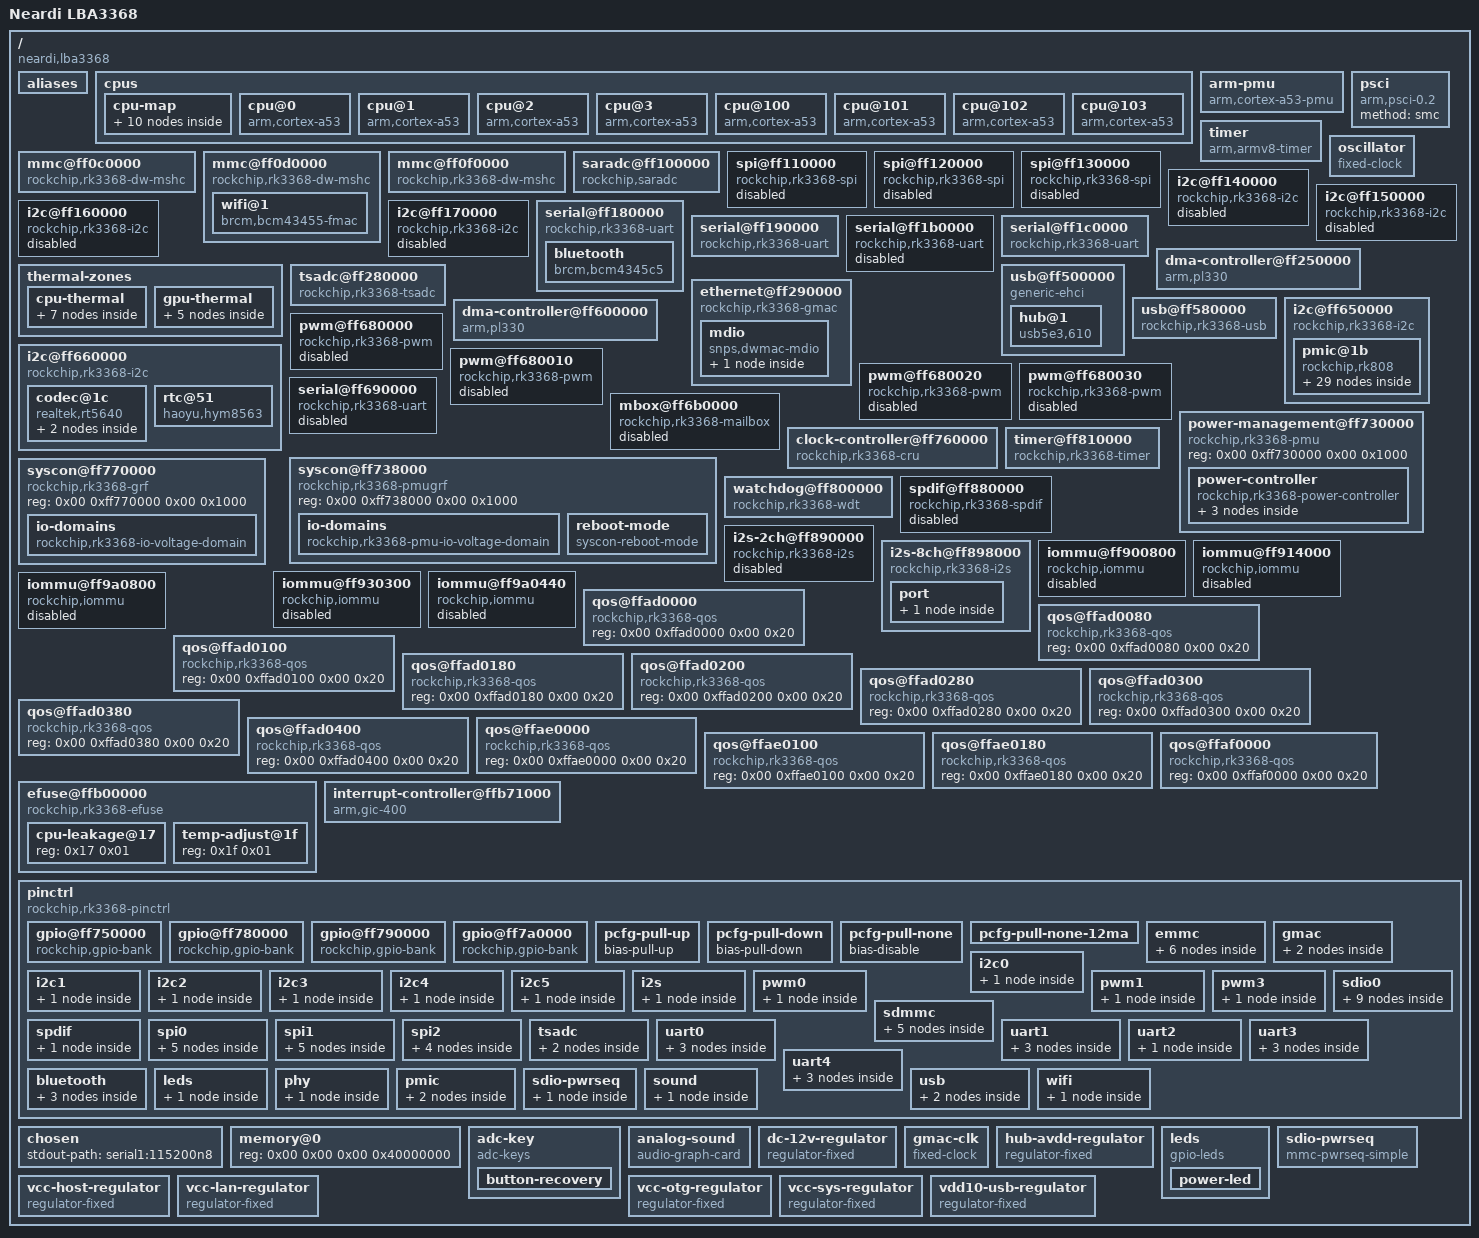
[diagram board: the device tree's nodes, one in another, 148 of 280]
/dts-v1/;

/ {
	compatible = "neardi,lba3368\0rockchip,rk3368";
	interrupt-parent = <0x01>;
	#address-cells = <0x02>;
	#size-cells = <0x02>;
	model = "Neardi LBA3368";

	aliases {
		gpio0 = "/pinctrl/gpio@ff750000";
		gpio1 = "/pinctrl/gpio@ff780000";
		gpio2 = "/pinctrl/gpio@ff790000";
		gpio3 = "/pinctrl/gpio@ff7a0000";
		i2c0 = "/i2c@ff650000";
		i2c1 = "/i2c@ff660000";
		i2c2 = "/i2c@ff140000";
		i2c3 = "/i2c@ff150000";
		i2c4 = "/i2c@ff160000";
		i2c5 = "/i2c@ff170000";
		serial0 = "/serial@ff180000";
		serial1 = "/serial@ff190000";
		serial2 = "/serial@ff690000";
		serial3 = "/serial@ff1b0000";
		serial4 = "/serial@ff1c0000";
		spi0 = "/spi@ff110000";
		spi1 = "/spi@ff120000";
		spi2 = "/spi@ff130000";
		ethernet0 = "/ethernet@ff290000";
		mmc0 = "/mmc@ff0f0000";
		mmc1 = "/mmc@ff0c0000";
		mmc2 = "/mmc@ff0d0000";
		rtc0 = "/i2c@ff660000/rtc@51";
		rtc1 = "/i2c@ff650000/pmic@1b";
	};

	cpus {
		#address-cells = <0x02>;
		#size-cells = <0x00>;

		cpu-map {

			cluster0 {

				core0 {
					cpu = <0x02>;
				};

				core1 {
					cpu = <0x03>;
				};

				core2 {
					cpu = <0x04>;
				};

				core3 {
					cpu = <0x05>;
				};
			};

			cluster1 {

				core0 {
					cpu = <0x06>;
				};

				core1 {
					cpu = <0x07>;
				};

				core2 {
					cpu = <0x08>;
				};

				core3 {
					cpu = <0x09>;
				};
			};
		};

		cpu@0 {
			device_type = "cpu";
			compatible = "arm,cortex-a53";
			reg = <0x00 0x00>;
			enable-method = "psci";
			#cooling-cells = <0x02>;
			cpu-supply = <0x0a>;
			phandle = <0x06>;
		};

		cpu@1 {
			device_type = "cpu";
			compatible = "arm,cortex-a53";
			reg = <0x00 0x01>;
			enable-method = "psci";
			#cooling-cells = <0x02>;
			cpu-supply = <0x0a>;
			phandle = <0x07>;
		};

		cpu@2 {
			device_type = "cpu";
			compatible = "arm,cortex-a53";
			reg = <0x00 0x02>;
			enable-method = "psci";
			#cooling-cells = <0x02>;
			cpu-supply = <0x0a>;
			phandle = <0x08>;
		};

		cpu@3 {
			device_type = "cpu";
			compatible = "arm,cortex-a53";
			reg = <0x00 0x03>;
			enable-method = "psci";
			#cooling-cells = <0x02>;
			cpu-supply = <0x0a>;
			phandle = <0x09>;
		};

		cpu@100 {
			device_type = "cpu";
			compatible = "arm,cortex-a53";
			reg = <0x00 0x100>;
			enable-method = "psci";
			#cooling-cells = <0x02>;
			cpu-supply = <0x0a>;
			phandle = <0x02>;
		};

		cpu@101 {
			device_type = "cpu";
			compatible = "arm,cortex-a53";
			reg = <0x00 0x101>;
			enable-method = "psci";
			#cooling-cells = <0x02>;
			cpu-supply = <0x0a>;
			phandle = <0x03>;
		};

		cpu@102 {
			device_type = "cpu";
			compatible = "arm,cortex-a53";
			reg = <0x00 0x102>;
			enable-method = "psci";
			#cooling-cells = <0x02>;
			cpu-supply = <0x0a>;
			phandle = <0x04>;
		};

		cpu@103 {
			device_type = "cpu";
			compatible = "arm,cortex-a53";
			reg = <0x00 0x103>;
			enable-method = "psci";
			#cooling-cells = <0x02>;
			cpu-supply = <0x0a>;
			phandle = <0x05>;
		};
	};

	arm-pmu {
		compatible = "arm,cortex-a53-pmu";
		interrupts = <0x00 0x70 0x04 0x00 0x71 0x04 0x00 0x72 0x04 0x00 0x73 0x04 0x00 0x74 0x04 0x00 0x75 0x04 0x00 0x76 0x04 0x00 0x77 0x04>;
		interrupt-affinity = <0x06 0x07 0x08 0x09 0x02 0x03 0x04 0x05>;
	};

	psci {
		compatible = "arm,psci-0.2";
		method = "smc";
	};

	timer {
		compatible = "arm,armv8-timer";
		interrupts = <0x01 0x0d 0xff04 0x01 0x0e 0xff04 0x01 0x0b 0xff04 0x01 0x0a 0xff04>;
	};

	oscillator {
		compatible = "fixed-clock";
		clock-frequency = <0x16e3600>;
		clock-output-names = "xin24m";
		#clock-cells = <0x00>;
		phandle = <0x5e>;
	};

	mmc@ff0c0000 {
		compatible = "rockchip,rk3368-dw-mshc\0rockchip,rk3288-dw-mshc";
		reg = <0x00 0xff0c0000 0x00 0x4000>;
		max-frequency = <0x8f0d180>;
		clocks = <0x0b 0x1c8 0x0b 0x44 0x0b 0x72 0x0b 0x76>;
		clock-names = "biu\0ciu\0ciu-drive\0ciu-sample";
		fifo-depth = <0x100>;
		interrupts = <0x00 0x20 0x04>;
		resets = <0x0b 0x80>;
		reset-names = "reset";
		status = "okay";
		bus-width = <0x04>;
		vmmc-supply = <0x0c>;
		vqmmc-supply = <0x0d>;
		pinctrl-names = "default";
		pinctrl-0 = <0x0e 0x0f 0x10 0x11>;
		cap-sd-highspeed;
		disable-wp;
		no-mmc;
		no-sdio;
		sd-uhs-sdr12;
		sd-uhs-sdr25;
		sd-uhs-sdr50;
		sd-uhs-sdr104;
	};

	mmc@ff0d0000 {
		compatible = "rockchip,rk3368-dw-mshc\0rockchip,rk3288-dw-mshc";
		reg = <0x00 0xff0d0000 0x00 0x4000>;
		max-frequency = <0x8f0d180>;
		clocks = <0x0b 0x1c9 0x0b 0x45 0x0b 0x73 0x0b 0x77>;
		clock-names = "biu\0ciu\0ciu-drive\0ciu-sample";
		fifo-depth = <0x100>;
		interrupts = <0x00 0x21 0x04>;
		resets = <0x0b 0x81>;
		reset-names = "reset";
		status = "okay";
		bus-width = <0x04>;
		mmc-pwrseq = <0x12>;
		vmmc-supply = <0x13>;
		vqmmc-supply = <0x14>;
		assigned-clocks = <0x0b 0x45>;
		assigned-clock-parents = <0x0b 0x04>;
		pinctrl-names = "default";
		pinctrl-0 = <0x15 0x16 0x17>;
		cap-sd-highspeed;
		cap-sdio-irq;
		no-sd;
		no-mmc;
		non-removable;
		sd-uhs-sdr104;
		#address-cells = <0x01>;
		#size-cells = <0x00>;

		wifi@1 {
			compatible = "brcm,bcm43455-fmac\0brcm,bcm4329-fmac";
			reg = <0x01>;
			interrupts-extended = <0x18 0x06 0x04>;
			interrupt-names = "host-wake";
			pinctrl-names = "default";
			pinctrl-0 = <0x19>;
		};
	};

	mmc@ff0f0000 {
		compatible = "rockchip,rk3368-dw-mshc\0rockchip,rk3288-dw-mshc";
		reg = <0x00 0xff0f0000 0x00 0x4000>;
		max-frequency = <0x8f0d180>;
		clocks = <0x0b 0x1cb 0x0b 0x47 0x0b 0x75 0x0b 0x79>;
		clock-names = "biu\0ciu\0ciu-drive\0ciu-sample";
		fifo-depth = <0x100>;
		interrupts = <0x00 0x23 0x04>;
		resets = <0x0b 0x83>;
		reset-names = "reset";
		status = "okay";
		bus-width = <0x08>;
		vmmc-supply = <0x13>;
		vqmmc-supply = <0x1a>;
		pinctrl-names = "default";
		pinctrl-0 = <0x1b 0x1c 0x1d>;
		cap-mmc-highspeed;
		non-removable;
		no-sd;
		no-sdio;
		mmc-hs200-1_8v;
	};

	saradc@ff100000 {
		compatible = "rockchip,saradc";
		reg = <0x00 0xff100000 0x00 0x100>;
		interrupts = <0x00 0x24 0x04>;
		#io-channel-cells = <0x01>;
		clocks = <0x0b 0x49 0x0b 0x15b>;
		clock-names = "saradc\0apb_pclk";
		resets = <0x0b 0x57>;
		reset-names = "saradc-apb";
		status = "okay";
		vref-supply = <0x1a>;
		phandle = <0x69>;
	};

	spi@ff110000 {
		compatible = "rockchip,rk3368-spi\0rockchip,rk3066-spi";
		reg = <0x00 0xff110000 0x00 0x1000>;
		clocks = <0x0b 0x41 0x0b 0x152>;
		clock-names = "spiclk\0apb_pclk";
		interrupts = <0x00 0x2c 0x04>;
		pinctrl-names = "default";
		pinctrl-0 = <0x1e 0x1f 0x20 0x21>;
		#address-cells = <0x01>;
		#size-cells = <0x00>;
		status = "disabled";
	};

	spi@ff120000 {
		compatible = "rockchip,rk3368-spi\0rockchip,rk3066-spi";
		reg = <0x00 0xff120000 0x00 0x1000>;
		clocks = <0x0b 0x42 0x0b 0x153>;
		clock-names = "spiclk\0apb_pclk";
		interrupts = <0x00 0x2d 0x04>;
		pinctrl-names = "default";
		pinctrl-0 = <0x22 0x23 0x24 0x25>;
		#address-cells = <0x01>;
		#size-cells = <0x00>;
		status = "disabled";
	};

	spi@ff130000 {
		compatible = "rockchip,rk3368-spi\0rockchip,rk3066-spi";
		reg = <0x00 0xff130000 0x00 0x1000>;
		clocks = <0x0b 0x43 0x0b 0x154>;
		clock-names = "spiclk\0apb_pclk";
		interrupts = <0x00 0x29 0x04>;
		pinctrl-names = "default";
		pinctrl-0 = <0x26 0x27 0x28 0x29>;
		#address-cells = <0x01>;
		#size-cells = <0x00>;
		status = "disabled";
	};

	i2c@ff140000 {
		compatible = "rockchip,rk3368-i2c\0rockchip,rk3288-i2c";
		reg = <0x00 0xff140000 0x00 0x1000>;
		interrupts = <0x00 0x3e 0x04>;
		#address-cells = <0x01>;
		#size-cells = <0x00>;
		clock-names = "i2c";
		clocks = <0x0b 0x14e>;
		pinctrl-names = "default";
		pinctrl-0 = <0x2a>;
		status = "disabled";
	};

	i2c@ff150000 {
		compatible = "rockchip,rk3368-i2c\0rockchip,rk3288-i2c";
		reg = <0x00 0xff150000 0x00 0x1000>;
		interrupts = <0x00 0x3f 0x04>;
		#address-cells = <0x01>;
		#size-cells = <0x00>;
		clock-names = "i2c";
		clocks = <0x0b 0x14f>;
		pinctrl-names = "default";
		pinctrl-0 = <0x2b>;
		status = "disabled";
	};

	i2c@ff160000 {
		compatible = "rockchip,rk3368-i2c\0rockchip,rk3288-i2c";
		reg = <0x00 0xff160000 0x00 0x1000>;
		interrupts = <0x00 0x40 0x04>;
		#address-cells = <0x01>;
		#size-cells = <0x00>;
		clock-names = "i2c";
		clocks = <0x0b 0x150>;
		pinctrl-names = "default";
		pinctrl-0 = <0x2c>;
		status = "disabled";
	};

	i2c@ff170000 {
		compatible = "rockchip,rk3368-i2c\0rockchip,rk3288-i2c";
		reg = <0x00 0xff170000 0x00 0x1000>;
		interrupts = <0x00 0x41 0x04>;
		#address-cells = <0x01>;
		#size-cells = <0x00>;
		clock-names = "i2c";
		clocks = <0x0b 0x151>;
		pinctrl-names = "default";
		pinctrl-0 = <0x2d>;
		status = "disabled";
	};

	serial@ff180000 {
		compatible = "rockchip,rk3368-uart\0snps,dw-apb-uart";
		reg = <0x00 0xff180000 0x00 0x100>;
		clock-frequency = <0x16e3600>;
		clocks = <0x0b 0x4d 0x0b 0x155>;
		clock-names = "baudclk\0apb_pclk";
		interrupts = <0x00 0x37 0x04>;
		reg-shift = <0x02>;
		reg-io-width = <0x04>;
		status = "okay";
		pinctrl-names = "default";
		pinctrl-0 = <0x2e 0x2f 0x30>;
		uart-has-rtscts;

		bluetooth {
			compatible = "brcm,bcm4345c5";
			interrupts-extended = <0x18 0x07 0x00>;
			interrupt-names = "host-wakeup";
			clocks = <0x31 0x01>;
			clock-names = "lpo";
			device-wakeup-gpios = <0x18 0x03 0x00>;
			shutdown-gpios = <0x18 0x02 0x00>;
			max-speed = <0xe4e1c0>;
			vbat-supply = <0x13>;
			vddio-supply = <0x14>;
			pinctrl-names = "default";
			pinctrl-0 = <0x32 0x33 0x34>;
		};
	};

	serial@ff190000 {
		compatible = "rockchip,rk3368-uart\0snps,dw-apb-uart";
		reg = <0x00 0xff190000 0x00 0x100>;
		clock-frequency = <0x16e3600>;
		clocks = <0x0b 0x4e 0x0b 0x156>;
		clock-names = "baudclk\0apb_pclk";
		interrupts = <0x00 0x38 0x04>;
		reg-shift = <0x02>;
		reg-io-width = <0x04>;
		status = "okay";
		pinctrl-names = "default";
		pinctrl-0 = <0x35>;
	};

	serial@ff1b0000 {
		compatible = "rockchip,rk3368-uart\0snps,dw-apb-uart";
		reg = <0x00 0xff1b0000 0x00 0x100>;
		clock-frequency = <0x16e3600>;
		clocks = <0x0b 0x50 0x0b 0x158>;
		clock-names = "baudclk\0apb_pclk";
		interrupts = <0x00 0x3a 0x04>;
		reg-shift = <0x02>;
		reg-io-width = <0x04>;
		status = "disabled";
	};

	serial@ff1c0000 {
		compatible = "rockchip,rk3368-uart\0snps,dw-apb-uart";
		reg = <0x00 0xff1c0000 0x00 0x100>;
		clock-frequency = <0x16e3600>;
		clocks = <0x0b 0x51 0x0b 0x159>;
		clock-names = "baudclk\0apb_pclk";
		interrupts = <0x00 0x3b 0x04>;
		reg-shift = <0x02>;
		reg-io-width = <0x04>;
		status = "okay";
		pinctrl-names = "default";
		pinctrl-0 = <0x36>;
	};

	dma-controller@ff250000 {
		compatible = "arm,pl330\0arm,primecell";
		reg = <0x00 0xff250000 0x00 0x4000>;
		interrupts = <0x00 0x02 0x04 0x00 0x03 0x04>;
		#dma-cells = <0x01>;
		arm,pl330-broken-no-flushp;
		arm,pl330-periph-burst;
		clocks = <0x0b 0xc3>;
		clock-names = "apb_pclk";
	};

	thermal-zones {

		cpu-thermal {
			polling-delay-passive = <0x64>;
			polling-delay = <0x1388>;
			thermal-sensors = <0x37 0x00>;

			trips {

				cpu_alert0 {
					temperature = <0x124f8>;
					hysteresis = <0x7d0>;
					type = "passive";
					phandle = <0x38>;
				};

				cpu_alert1 {
					temperature = <0x13880>;
					hysteresis = <0x7d0>;
					type = "passive";
					phandle = <0x39>;
				};

				cpu_crit {
					temperature = <0x17318>;
					hysteresis = <0x7d0>;
					type = "critical";
				};
			};

			cooling-maps {

				map0 {
					trip = <0x38>;
					cooling-device = <0x02 0xffffffff 0xffffffff 0x03 0xffffffff 0xffffffff 0x04 0xffffffff 0xffffffff 0x05 0xffffffff 0xffffffff>;
				};

				map1 {
					trip = <0x39>;
					cooling-device = <0x06 0xffffffff 0xffffffff 0x07 0xffffffff 0xffffffff 0x08 0xffffffff 0xffffffff 0x09 0xffffffff 0xffffffff>;
				};
			};
		};

		gpu-thermal {
			polling-delay-passive = <0x64>;
			polling-delay = <0x1388>;
			thermal-sensors = <0x37 0x01>;

			trips {

				gpu_alert0 {
					temperature = <0x13880>;
					hysteresis = <0x7d0>;
					type = "passive";
					phandle = <0x3a>;
				};

				gpu_crit {
					temperature = <0x1c138>;
					hysteresis = <0x7d0>;
					type = "critical";
				};
			};

			cooling-maps {

				map0 {
					trip = <0x3a>;
					cooling-device = <0x02 0xffffffff 0xffffffff 0x03 0xffffffff 0xffffffff 0x04 0xffffffff 0xffffffff 0x05 0xffffffff 0xffffffff>;
				};
			};
		};
	};

	tsadc@ff280000 {
		compatible = "rockchip,rk3368-tsadc";
		reg = <0x00 0xff280000 0x00 0x100>;
		interrupts = <0x00 0x25 0x04>;
		clocks = <0x0b 0x48 0x0b 0x15a>;
		clock-names = "tsadc\0apb_pclk";
		resets = <0x0b 0x9f>;
		reset-names = "tsadc-apb";
		pinctrl-names = "init\0default\0sleep";
		pinctrl-0 = <0x3b>;
		pinctrl-1 = <0x3c>;
		pinctrl-2 = <0x3b>;
		#thermal-sensor-cells = <0x01>;
		rockchip,hw-tshut-temp = <0x17318>;
		status = "okay";
		rockchip,hw-tshut-mode = <0x00>;
		rockchip,hw-tshut-polarity = <0x01>;
		phandle = <0x37>;
	};

	ethernet@ff290000 {
		compatible = "rockchip,rk3368-gmac";
		reg = <0x00 0xff290000 0x00 0x10000>;
		interrupts = <0x00 0x1b 0x04>;
		interrupt-names = "macirq";
		rockchip,grf = <0x3d>;
		clocks = <0x0b 0x7f 0x0b 0x66 0x0b 0x67 0x0b 0x63 0x0b 0x80 0x0b 0xc5 0x0b 0x15d>;
		clock-names = "stmmaceth\0mac_clk_rx\0mac_clk_tx\0clk_mac_ref\0clk_mac_refout\0aclk_mac\0pclk_mac";
		status = "okay";
		clock_in_out = "input";
		phy-handle = <0x3e>;
		phy-mode = "rmii";
		phy-supply = <0x3f>;
		assigned-clocks = <0x0b 0x7f>;
		assigned-clock-parents = <0x40>;
		pinctrl-names = "default";
		pinctrl-0 = <0x41>;

		mdio {
			compatible = "snps,dwmac-mdio";
			#address-cells = <0x01>;
			#size-cells = <0x00>;

			ethernet-phy@1 {
				compatible = "ethernet-phy-ieee802.3-c22";
				reg = <0x01>;
				max-speed = <0x64>;
				reset-assert-us = <0x2710>;
				reset-deassert-us = <0xf4240>;
				reset-gpios = <0x18 0x0c 0x01>;
				pinctrl-names = "default";
				pinctrl-0 = <0x42>;
				phandle = <0x3e>;
			};
		};
	};

	usb@ff500000 {
		compatible = "generic-ehci";
		reg = <0x00 0xff500000 0x00 0x100>;
		interrupts = <0x00 0x18 0x04>;
		clocks = <0x0b 0x1c2>;
		status = "okay";
		#address-cells = <0x01>;
		#size-cells = <0x00>;

		hub@1 {
			compatible = "usb5e3,610";
			reg = <0x01>;
			vdd-supply = <0x43>;
		};
	};

	usb@ff580000 {
		compatible = "rockchip,rk3368-usb\0rockchip,rk3066-usb\0snps,dwc2";
		reg = <0x00 0xff580000 0x00 0x40000>;
		interrupts = <0x00 0x17 0x04>;
		clocks = <0x0b 0x1c1>;
		clock-names = "otg";
		dr_mode = "otg";
		g-np-tx-fifo-size = <0x10>;
		g-rx-fifo-size = <0x113>;
		g-tx-fifo-size = <0x100 0x80 0x80 0x40 0x40 0x20>;
		status = "okay";
		vbus-supply = <0x44>;
		vusb_a-supply = <0x13>;
		vusb_d-supply = <0x45>;
	};

	dma-controller@ff600000 {
		compatible = "arm,pl330\0arm,primecell";
		reg = <0x00 0xff600000 0x00 0x4000>;
		interrupts = <0x00 0x00 0x04 0x00 0x01 0x04>;
		#dma-cells = <0x01>;
		arm,pl330-broken-no-flushp;
		arm,pl330-periph-burst;
		clocks = <0x0b 0xc2>;
		clock-names = "apb_pclk";
		phandle = <0x60>;
	};

	i2c@ff650000 {
		compatible = "rockchip,rk3368-i2c\0rockchip,rk3288-i2c";
		reg = <0x00 0xff650000 0x00 0x1000>;
		clocks = <0x0b 0x14c>;
		clock-names = "i2c";
		interrupts = <0x00 0x3c 0x04>;
		pinctrl-names = "default";
		pinctrl-0 = <0x46>;
		#address-cells = <0x01>;
		#size-cells = <0x00>;
		status = "okay";

		pmic@1b {
			compatible = "rockchip,rk808";
			reg = <0x1b>;
			interrupts-extended = <0x47 0x05 0x08>;
			clock-output-names = "rk808-clkout1\0xin32k_wifi_bt";
			vcc1-supply = <0x48>;
			vcc2-supply = <0x48>;
			vcc3-supply = <0x48>;
			vcc4-supply = <0x48>;
			vcc6-supply = <0x48>;
			vcc7-supply = <0x48>;
			vcc8-supply = <0x13>;
			vcc9-supply = <0x48>;
			vcc10-supply = <0x48>;
			vcc11-supply = <0x48>;
			vcc12-supply = <0x13>;
			pinctrl-names = "default";
			pinctrl-0 = <0x49 0x4a>;
			system-power-controller;
			wakeup-source;
			#clock-cells = <0x01>;
			phandle = <0x31>;

			regulators {

				DCDC_REG1 {
					regulator-name = "vdd_cpu";
					regulator-min-microvolt = <0xaae60>;
					regulator-max-microvolt = <0x149970>;
					regulator-always-on;
					regulator-boot-on;
					phandle = <0x0a>;

					regulator-state-mem {
						regulator-off-in-suspend;
					};
				};

				DCDC_REG2 {
					regulator-name = "vdd_log";
					regulator-min-microvolt = <0x10c8e0>;
					regulator-max-microvolt = <0x16e360>;
					regulator-ramp-delay = <0x1771>;
					regulator-always-on;
					regulator-boot-on;

					regulator-state-mem {
						regulator-suspend-microvolt = <0xf4240>;
						regulator-on-in-suspend;
					};
				};

				DCDC_REG3 {
					regulator-name = "vcc_ddr";
					regulator-always-on;
					regulator-boot-on;

					regulator-state-mem {
						regulator-on-in-suspend;
					};
				};

				DCDC_REG4 {
					regulator-name = "vcc_io";
					regulator-min-microvolt = <0x325aa0>;
					regulator-max-microvolt = <0x325aa0>;
					regulator-always-on;
					regulator-boot-on;
					phandle = <0x13>;

					regulator-state-mem {
						regulator-suspend-microvolt = <0x325aa0>;
						regulator-on-in-suspend;
					};
				};

				LDO_REG1 {
					regulator-name = "vcca1v8_codec";
					regulator-min-microvolt = <0x1b7740>;
					regulator-max-microvolt = <0x1b7740>;
					regulator-always-on;
					phandle = <0x5f>;

					regulator-state-mem {
						regulator-off-in-suspend;
					};
				};

				LDO_REG2 {
					regulator-name = "vcca3v0_codec";
					regulator-min-microvolt = <0x2dc6c0>;
					regulator-max-microvolt = <0x2dc6c0>;
					regulator-always-on;

					regulator-state-mem {
						regulator-off-in-suspend;
					};
				};

				LDO_REG3 {
					regulator-name = "vdd_10";
					regulator-min-microvolt = <0xf4240>;
					regulator-max-microvolt = <0xf4240>;
					regulator-always-on;
					regulator-boot-on;
					phandle = <0x71>;

					regulator-state-mem {
						regulator-suspend-microvolt = <0xf4240>;
						regulator-on-in-suspend;
					};
				};

				LDO_REG4 {
					regulator-name = "vdd1v8_wl";
					regulator-min-microvolt = <0x1b7740>;
					regulator-max-microvolt = <0x1b7740>;
					phandle = <0x14>;

					regulator-state-mem {
						regulator-off-in-suspend;
					};
				};

				LDO_REG5 {
					regulator-name = "vccio_sd";
					regulator-min-microvolt = <0x1b7740>;
					regulator-max-microvolt = <0x325aa0>;
					phandle = <0x0d>;

					regulator-state-mem {
						regulator-off-in-suspend;
					};
				};

				LDO_REG6 {
					regulator-name = "vdd10_lcd";
					regulator-min-microvolt = <0xf4240>;
					regulator-max-microvolt = <0xf4240>;

					regulator-state-mem {
						regulator-off-in-suspend;
					};
				};

				LDO_REG7 {
					regulator-name = "vcc_18";
					regulator-min-microvolt = <0x1b7740>;
					regulator-max-microvolt = <0x1b7740>;
					phandle = <0x1a>;

					regulator-state-mem {
						regulator-suspend-microvolt = <0x1b7740>;
						regulator-on-in-suspend;
					};
				};

				LDO_REG8 {
					regulator-name = "vcc18_lcd";
					regulator-min-microvolt = <0x1b7740>;
					regulator-max-microvolt = <0x1b7740>;

					regulator-state-mem {
						regulator-off-in-suspend;
					};
				};

				SWITCH_REG1 {
					regulator-name = "vcc_tp";

					regulator-state-mem {
						regulator-on-in-suspend;
					};
				};

				SWITCH_REG2 {
					regulator-name = "vcc_sd";
					phandle = <0x0c>;

					regulator-state-mem {
						regulator-off-in-suspend;
					};
				};
			};
		};
	};

	i2c@ff660000 {
		compatible = "rockchip,rk3368-i2c\0rockchip,rk3288-i2c";
		reg = <0x00 0xff660000 0x00 0x1000>;
		interrupts = <0x00 0x3d 0x04>;
		#address-cells = <0x01>;
		#size-cells = <0x00>;
		clock-names = "i2c";
		clocks = <0x0b 0x14d>;
		pinctrl-names = "default";
		pinctrl-0 = <0x4b>;
		status = "okay";

		codec@1c {
			compatible = "realtek,rt5640";
			reg = <0x1c>;
			clocks = <0x0b 0x71>;
			clock-names = "mclk";
			realtek,dmic1-data-pin = <0x01>;
			realtek,dmic2-data-pin = <0x01>;
			realtek,in1-differential;
			#sound-dai-cells = <0x00>;

			port {

				endpoint {
					remote-endpoint = <0x4c>;
					phandle = <0x63>;
				};
			};
		};

		rtc@51 {
			compatible = "haoyu,hym8563";
			reg = <0x51>;
			clock-output-names = "xin32k";
			#clock-cells = <0x00>;
		};
	};

	pwm@ff680000 {
		compatible = "rockchip,rk3368-pwm\0rockchip,rk3288-pwm";
		reg = <0x00 0xff680000 0x00 0x10>;
		#pwm-cells = <0x03>;
		pinctrl-names = "default";
		pinctrl-0 = <0x4d>;
		clocks = <0x0b 0x15f>;
		status = "disabled";
	};

	pwm@ff680010 {
		compatible = "rockchip,rk3368-pwm\0rockchip,rk3288-pwm";
		reg = <0x00 0xff680010 0x00 0x10>;
		#pwm-cells = <0x03>;
		pinctrl-names = "default";
		pinctrl-0 = <0x4e>;
		clocks = <0x0b 0x15f>;
		status = "disabled";
	};

	pwm@ff680020 {
		compatible = "rockchip,rk3368-pwm\0rockchip,rk3288-pwm";
		reg = <0x00 0xff680020 0x00 0x10>;
		#pwm-cells = <0x03>;
		clocks = <0x0b 0x15f>;
		status = "disabled";
	};

	pwm@ff680030 {
		compatible = "rockchip,rk3368-pwm\0rockchip,rk3288-pwm";
		reg = <0x00 0xff680030 0x00 0x10>;
		#pwm-cells = <0x03>;
		pinctrl-names = "default";
		pinctrl-0 = <0x4f>;
		clocks = <0x0b 0x15f>;
		status = "disabled";
	};

	serial@ff690000 {
		compatible = "rockchip,rk3368-uart\0snps,dw-apb-uart";
		reg = <0x00 0xff690000 0x00 0x100>;
		clocks = <0x0b 0x4f 0x0b 0x157>;
		clock-names = "baudclk\0apb_pclk";
		interrupts = <0x00 0x39 0x04>;
		pinctrl-names = "default";
		pinctrl-0 = <0x50>;
		reg-shift = <0x02>;
		reg-io-width = <0x04>;
		status = "disabled";
	};

	mbox@ff6b0000 {
		compatible = "rockchip,rk3368-mailbox";
		reg = <0x00 0xff6b0000 0x00 0x1000>;
		interrupts = <0x00 0x92 0x04 0x00 0x93 0x04 0x00 0x94 0x04 0x00 0x95 0x04>;
		clocks = <0x0b 0x145>;
		clock-names = "pclk_mailbox";
		#mbox-cells = <0x01>;
		status = "disabled";
	};

	power-management@ff730000 {
		compatible = "rockchip,rk3368-pmu\0syscon\0simple-mfd";
		reg = <0x00 0xff730000 0x00 0x1000>;

		power-controller {
			compatible = "rockchip,rk3368-power-controller";
			#power-domain-cells = <0x01>;
			#address-cells = <0x01>;
			#size-cells = <0x00>;
			phandle = <0x64>;

			power-domain@12 {
				reg = <0x0c>;
				clocks = <0x0b 0xca 0x0b 0xcd 0x0b 0xcc 0x0b 0xc8 0x0b 0xc6 0x0b 0xc7 0x0b 0xbe 0x0b 0x1d4 0x0b 0x1d5 0x0b 0x1d6 0x0b 0x1d9 0x0b 0x1d1 0x0b 0x1db 0x0b 0x163 0x0b 0x168 0x0b 0x167 0x0b 0x16e 0x0b 0x16f 0x0b 0x172 0x0b 0x173 0x0b 0x166 0x0b 0x164 0x0b 0x64 0x0b 0x68 0x0b 0x69 0x0b 0x6c 0x0b 0x6b 0x0b 0x6a 0x0b 0x6e 0x0b 0x6d>;
				pm_qos = <0x51 0x52 0x53 0x54 0x55 0x56 0x57 0x58 0x59>;
				#power-domain-cells = <0x00>;
			};

			power-domain@14 {
				reg = <0x0e>;
				clocks = <0x0b 0xd0 0x0b 0x1dc 0x0b 0x6f 0x0b 0x70>;
				pm_qos = <0x5a 0x5b 0x5c>;
				#power-domain-cells = <0x00>;
			};

			power-domain@16 {
				reg = <0x10>;
				clocks = <0x0b 0xc1 0x0b 0xc0 0x0b 0x40>;
				pm_qos = <0x5d>;
				#power-domain-cells = <0x00>;
			};
		};
	};

	syscon@ff738000 {
		compatible = "rockchip,rk3368-pmugrf\0syscon\0simple-mfd";
		reg = <0x00 0xff738000 0x00 0x1000>;
		phandle = <0x65>;

		io-domains {
			compatible = "rockchip,rk3368-pmu-io-voltage-domain";
			status = "okay";
			pmu-supply = <0x13>;
			vop-supply = <0x13>;
		};

		reboot-mode {
			compatible = "syscon-reboot-mode";
			offset = <0x200>;
			mode-normal = <0x5242c300>;
			mode-recovery = <0x5242c303>;
			mode-bootloader = <0x5242c309>;
			mode-loader = <0x5242c301>;
		};
	};

	clock-controller@ff760000 {
		compatible = "rockchip,rk3368-cru";
		reg = <0x00 0xff760000 0x00 0x1000>;
		clocks = <0x5e>;
		clock-names = "xin24m";
		rockchip,grf = <0x3d>;
		#clock-cells = <0x01>;
		#reset-cells = <0x01>;
		phandle = <0x0b>;
	};

	syscon@ff770000 {
		compatible = "rockchip,rk3368-grf\0syscon\0simple-mfd";
		reg = <0x00 0xff770000 0x00 0x1000>;
		phandle = <0x3d>;

		io-domains {
			compatible = "rockchip,rk3368-io-voltage-domain";
			status = "okay";
			audio-supply = <0x5f>;
			dvp-supply = <0x1a>;
			flash0-supply = <0x1a>;
			gpio1830-supply = <0x13>;
			gpio30-supply = <0x13>;
			sdcard-supply = <0x0d>;
			wifi-supply = <0x14>;
		};
	};

	watchdog@ff800000 {
		compatible = "rockchip,rk3368-wdt\0snps,dw-wdt";
		reg = <0x00 0xff800000 0x00 0x100>;
		clocks = <0x0b 0x170>;
		interrupts = <0x00 0x4f 0x04>;
		status = "okay";
	};

	timer@ff810000 {
		compatible = "rockchip,rk3368-timer\0rockchip,rk3288-timer";
		reg = <0x00 0xff810000 0x00 0x20>;
		interrupts = <0x00 0x42 0x04>;
		clocks = <0x0b 0x161 0x0b 0x55>;
		clock-names = "pclk\0timer";
	};

	spdif@ff880000 {
		compatible = "rockchip,rk3368-spdif";
		reg = <0x00 0xff880000 0x00 0x1000>;
		interrupts = <0x00 0x36 0x04>;
		clocks = <0x0b 0x53 0x0b 0x1d0>;
		clock-names = "mclk\0hclk";
		dmas = <0x60 0x03>;
		dma-names = "tx";
		pinctrl-names = "default";
		pinctrl-0 = <0x61>;
		#sound-dai-cells = <0x00>;
		status = "disabled";
	};

	i2s-2ch@ff890000 {
		compatible = "rockchip,rk3368-i2s\0rockchip,rk3066-i2s";
		reg = <0x00 0xff890000 0x00 0x1000>;
		interrupts = <0x00 0x28 0x04>;
		clock-names = "i2s_clk\0i2s_hclk";
		clocks = <0x0b 0x54 0x0b 0x1ce>;
		dmas = <0x60 0x06 0x60 0x07>;
		dma-names = "tx\0rx";
		#sound-dai-cells = <0x00>;
		status = "disabled";
	};

	i2s-8ch@ff898000 {
		compatible = "rockchip,rk3368-i2s\0rockchip,rk3066-i2s";
		reg = <0x00 0xff898000 0x00 0x1000>;
		interrupts = <0x00 0x35 0x04>;
		clock-names = "i2s_clk\0i2s_hclk";
		clocks = <0x0b 0x52 0x0b 0x1cf>;
		dmas = <0x60 0x00 0x60 0x01>;
		dma-names = "tx\0rx";
		pinctrl-names = "default";
		pinctrl-0 = <0x62>;
		#sound-dai-cells = <0x00>;
		status = "okay";

		port {
			phandle = <0x6a>;

			endpoint {
				dai-format = "i2s";
				mclk-fs = <0x100>;
				remote-endpoint = <0x63>;
				phandle = <0x4c>;
			};
		};
	};

	iommu@ff900800 {
		compatible = "rockchip,iommu";
		reg = <0x00 0xff900800 0x00 0x100>;
		interrupts = <0x00 0x11 0x04>;
		clocks = <0x0b 0xca 0x0b 0x1d4>;
		clock-names = "aclk\0iface";
		power-domains = <0x64 0x0c>;
		#iommu-cells = <0x00>;
		status = "disabled";
	};

	iommu@ff914000 {
		compatible = "rockchip,iommu";
		reg = <0x00 0xff914000 0x00 0x100 0x00 0xff915000 0x00 0x100>;
		interrupts = <0x00 0x0e 0x04>;
		clocks = <0x0b 0xcd 0x0b 0x1d5>;
		clock-names = "aclk\0iface";
		#iommu-cells = <0x00>;
		power-domains = <0x64 0x0c>;
		rockchip,disable-mmu-reset;
		status = "disabled";
	};

	iommu@ff930300 {
		compatible = "rockchip,iommu";
		reg = <0x00 0xff930300 0x00 0x100>;
		interrupts = <0x00 0x0f 0x04>;
		clocks = <0x0b 0xc6 0x0b 0x1d1>;
		clock-names = "aclk\0iface";
		power-domains = <0x64 0x0c>;
		#iommu-cells = <0x00>;
		status = "disabled";
	};

	iommu@ff9a0440 {
		compatible = "rockchip,iommu";
		reg = <0x00 0xff9a0440 0x00 0x40 0x00 0xff9a0480 0x00 0x40>;
		interrupts = <0x00 0x0c 0x04>;
		clocks = <0x0b 0xd0 0x0b 0x1dc>;
		clock-names = "aclk\0iface";
		#iommu-cells = <0x00>;
		status = "disabled";
	};

	iommu@ff9a0800 {
		compatible = "rockchip,iommu";
		reg = <0x00 0xff9a0800 0x00 0x100>;
		interrupts = <0x00 0x09 0x04 0x00 0x0a 0x04>;
		clocks = <0x0b 0xd0 0x0b 0x1dc>;
		clock-names = "aclk\0iface";
		#iommu-cells = <0x00>;
		status = "disabled";
	};

	qos@ffad0000 {
		compatible = "rockchip,rk3368-qos\0syscon";
		reg = <0x00 0xffad0000 0x00 0x20>;
		phandle = <0x51>;
	};

	qos@ffad0080 {
		compatible = "rockchip,rk3368-qos\0syscon";
		reg = <0x00 0xffad0080 0x00 0x20>;
		phandle = <0x52>;
	};

	qos@ffad0100 {
		compatible = "rockchip,rk3368-qos\0syscon";
		reg = <0x00 0xffad0100 0x00 0x20>;
		phandle = <0x53>;
	};

	qos@ffad0180 {
		compatible = "rockchip,rk3368-qos\0syscon";
		reg = <0x00 0xffad0180 0x00 0x20>;
		phandle = <0x54>;
	};

	qos@ffad0200 {
		compatible = "rockchip,rk3368-qos\0syscon";
		reg = <0x00 0xffad0200 0x00 0x20>;
		phandle = <0x55>;
	};

	qos@ffad0280 {
		compatible = "rockchip,rk3368-qos\0syscon";
		reg = <0x00 0xffad0280 0x00 0x20>;
		phandle = <0x56>;
	};

	qos@ffad0300 {
		compatible = "rockchip,rk3368-qos\0syscon";
		reg = <0x00 0xffad0300 0x00 0x20>;
		phandle = <0x57>;
	};

	qos@ffad0380 {
		compatible = "rockchip,rk3368-qos\0syscon";
		reg = <0x00 0xffad0380 0x00 0x20>;
		phandle = <0x58>;
	};

	qos@ffad0400 {
		compatible = "rockchip,rk3368-qos\0syscon";
		reg = <0x00 0xffad0400 0x00 0x20>;
		phandle = <0x59>;
	};

	qos@ffae0000 {
		compatible = "rockchip,rk3368-qos\0syscon";
		reg = <0x00 0xffae0000 0x00 0x20>;
		phandle = <0x5a>;
	};

	qos@ffae0100 {
		compatible = "rockchip,rk3368-qos\0syscon";
		reg = <0x00 0xffae0100 0x00 0x20>;
		phandle = <0x5b>;
	};

	qos@ffae0180 {
		compatible = "rockchip,rk3368-qos\0syscon";
		reg = <0x00 0xffae0180 0x00 0x20>;
		phandle = <0x5c>;
	};

	qos@ffaf0000 {
		compatible = "rockchip,rk3368-qos\0syscon";
		reg = <0x00 0xffaf0000 0x00 0x20>;
		phandle = <0x5d>;
	};

	efuse@ffb00000 {
		compatible = "rockchip,rk3368-efuse";
		reg = <0x00 0xffb00000 0x00 0x20>;
		#address-cells = <0x01>;
		#size-cells = <0x01>;
		clocks = <0x0b 0x171>;
		clock-names = "pclk_efuse";

		cpu-leakage@17 {
			reg = <0x17 0x01>;
		};

		temp-adjust@1f {
			reg = <0x1f 0x01>;
		};
	};

	interrupt-controller@ffb71000 {
		compatible = "arm,gic-400";
		interrupt-controller;
		#interrupt-cells = <0x03>;
		#address-cells = <0x00>;
		reg = <0x00 0xffb71000 0x00 0x1000 0x00 0xffb72000 0x00 0x2000 0x00 0xffb74000 0x00 0x2000 0x00 0xffb76000 0x00 0x2000>;
		interrupts = <0x01 0x09 0xff04>;
		phandle = <0x01>;
	};

	pinctrl {
		compatible = "rockchip,rk3368-pinctrl";
		rockchip,grf = <0x3d>;
		rockchip,pmu = <0x65>;
		#address-cells = <0x02>;
		#size-cells = <0x02>;
		ranges;

		gpio@ff750000 {
			compatible = "rockchip,gpio-bank";
			reg = <0x00 0xff750000 0x00 0x100>;
			clocks = <0x0b 0x140>;
			interrupts = <0x00 0x51 0x04>;
			gpio-controller;
			#gpio-cells = <0x02>;
			interrupt-controller;
			#interrupt-cells = <0x02>;
			phandle = <0x47>;
		};

		gpio@ff780000 {
			compatible = "rockchip,gpio-bank";
			reg = <0x00 0xff780000 0x00 0x100>;
			clocks = <0x0b 0x141>;
			interrupts = <0x00 0x52 0x04>;
			gpio-controller;
			#gpio-cells = <0x02>;
			interrupt-controller;
			#interrupt-cells = <0x02>;
		};

		gpio@ff790000 {
			compatible = "rockchip,gpio-bank";
			reg = <0x00 0xff790000 0x00 0x100>;
			clocks = <0x0b 0x142>;
			interrupts = <0x00 0x53 0x04>;
			gpio-controller;
			#gpio-cells = <0x02>;
			interrupt-controller;
			#interrupt-cells = <0x02>;
		};

		gpio@ff7a0000 {
			compatible = "rockchip,gpio-bank";
			reg = <0x00 0xff7a0000 0x00 0x100>;
			clocks = <0x0b 0x143>;
			interrupts = <0x00 0x54 0x04>;
			gpio-controller;
			#gpio-cells = <0x02>;
			interrupt-controller;
			#interrupt-cells = <0x02>;
			phandle = <0x18>;
		};

		pcfg-pull-up {
			bias-pull-up;
			phandle = <0x67>;
		};

		pcfg-pull-down {
			bias-pull-down;
		};

		pcfg-pull-none {
			bias-disable;
			phandle = <0x66>;
		};

		pcfg-pull-none-12ma {
			bias-disable;
			drive-strength = <0x0c>;
			phandle = <0x68>;
		};

		emmc {

			emmc-clk {
				rockchip,pins = <0x02 0x04 0x02 0x66>;
				phandle = <0x1b>;
			};

			emmc-cmd {
				rockchip,pins = <0x01 0x1a 0x02 0x67>;
				phandle = <0x1c>;
			};

			emmc-pwr {
				rockchip,pins = <0x01 0x1b 0x02 0x67>;
			};

			emmc-bus1 {
				rockchip,pins = <0x01 0x12 0x02 0x67>;
			};

			emmc-bus4 {
				rockchip,pins = <0x01 0x12 0x02 0x67 0x01 0x13 0x02 0x67 0x01 0x14 0x02 0x67 0x01 0x15 0x02 0x67>;
			};

			emmc-bus8 {
				rockchip,pins = <0x01 0x12 0x02 0x67 0x01 0x13 0x02 0x67 0x01 0x14 0x02 0x67 0x01 0x15 0x02 0x67 0x01 0x16 0x02 0x67 0x01 0x17 0x02 0x67 0x01 0x18 0x02 0x67 0x01 0x19 0x02 0x67>;
				phandle = <0x1d>;
			};
		};

		gmac {

			rgmii-pins {
				rockchip,pins = <0x03 0x16 0x01 0x66 0x03 0x18 0x01 0x66 0x03 0x13 0x01 0x66 0x03 0x08 0x01 0x68 0x03 0x09 0x01 0x68 0x03 0x0a 0x01 0x68 0x03 0x0e 0x01 0x68 0x03 0x1c 0x01 0x68 0x03 0x0d 0x01 0x68 0x03 0x0f 0x01 0x66 0x03 0x10 0x01 0x66 0x03 0x11 0x01 0x66 0x03 0x12 0x01 0x66 0x03 0x19 0x01 0x66 0x03 0x14 0x01 0x66>;
			};

			rmii-pins {
				rockchip,pins = <0x03 0x16 0x01 0x66 0x03 0x18 0x01 0x66 0x03 0x13 0x01 0x66 0x03 0x08 0x01 0x68 0x03 0x09 0x01 0x68 0x03 0x0d 0x01 0x68 0x03 0x0f 0x01 0x66 0x03 0x10 0x01 0x66 0x03 0x14 0x01 0x66 0x03 0x15 0x01 0x66>;
				phandle = <0x41>;
			};
		};

		i2c0 {

			i2c0-xfer {
				rockchip,pins = <0x00 0x06 0x01 0x66 0x00 0x07 0x01 0x66>;
				phandle = <0x46>;
			};
		};

		i2c1 {

			i2c1-xfer {
				rockchip,pins = <0x02 0x15 0x01 0x66 0x02 0x16 0x01 0x66>;
				phandle = <0x4b>;
			};
		};

		i2c2 {

			i2c2-xfer {
				rockchip,pins = <0x00 0x09 0x02 0x66 0x03 0x1f 0x02 0x66>;
				phandle = <0x2a>;
			};
		};

		i2c3 {

			i2c3-xfer {
				rockchip,pins = <0x01 0x10 0x01 0x66 0x01 0x11 0x01 0x66>;
				phandle = <0x2b>;
			};
		};

		i2c4 {

			i2c4-xfer {
				rockchip,pins = <0x03 0x18 0x02 0x66 0x03 0x19 0x02 0x66>;
				phandle = <0x2c>;
			};
		};

		i2c5 {

			i2c5-xfer {
				rockchip,pins = <0x03 0x1a 0x02 0x66 0x03 0x1b 0x02 0x66>;
				phandle = <0x2d>;
			};
		};

		i2s {

			i2s-8ch-bus {
				rockchip,pins = <0x02 0x0c 0x01 0x66 0x02 0x0d 0x01 0x66 0x02 0x0e 0x01 0x66 0x02 0x0f 0x01 0x66 0x02 0x10 0x01 0x66 0x02 0x11 0x01 0x66 0x02 0x12 0x01 0x66 0x02 0x13 0x01 0x66 0x02 0x14 0x01 0x66>;
				phandle = <0x62>;
			};
		};

		pwm0 {

			pwm0-pin {
				rockchip,pins = <0x03 0x08 0x02 0x66>;
				phandle = <0x4d>;
			};
		};

		pwm1 {

			pwm1-pin {
				rockchip,pins = <0x00 0x08 0x02 0x66>;
				phandle = <0x4e>;
			};
		};

		pwm3 {

			pwm3-pin {
				rockchip,pins = <0x03 0x1d 0x03 0x66>;
				phandle = <0x4f>;
			};
		};

		sdio0 {

			sdio0-bus1 {
				rockchip,pins = <0x02 0x1c 0x01 0x67>;
			};

			sdio0-bus4 {
				rockchip,pins = <0x02 0x1c 0x01 0x67 0x02 0x1d 0x01 0x67 0x02 0x1e 0x01 0x67 0x02 0x1f 0x01 0x67>;
				phandle = <0x15>;
			};

			sdio0-cmd {
				rockchip,pins = <0x03 0x00 0x01 0x67>;
				phandle = <0x16>;
			};

			sdio0-clk {
				rockchip,pins = <0x03 0x01 0x01 0x66>;
				phandle = <0x17>;
			};

			sdio0-cd {
				rockchip,pins = <0x03 0x02 0x01 0x67>;
			};

			sdio0-wp {
				rockchip,pins = <0x03 0x03 0x01 0x67>;
			};

			sdio0-pwr {
				rockchip,pins = <0x03 0x04 0x01 0x67>;
			};

			sdio0-bkpwr {
				rockchip,pins = <0x03 0x05 0x01 0x67>;
			};

			sdio0-int {
				rockchip,pins = <0x03 0x06 0x01 0x67>;
			};
		};

		sdmmc {

			sdmmc-clk {
				rockchip,pins = <0x02 0x09 0x01 0x66>;
				phandle = <0x0e>;
			};

			sdmmc-cmd {
				rockchip,pins = <0x02 0x0a 0x01 0x67>;
				phandle = <0x0f>;
			};

			sdmmc-cd {
				rockchip,pins = <0x02 0x0b 0x01 0x67>;
				phandle = <0x11>;
			};

			sdmmc-bus1 {
				rockchip,pins = <0x02 0x05 0x01 0x67>;
			};

			sdmmc-bus4 {
				rockchip,pins = <0x02 0x05 0x01 0x67 0x02 0x06 0x01 0x67 0x02 0x07 0x01 0x67 0x02 0x08 0x01 0x67>;
				phandle = <0x10>;
			};
		};

		spdif {

			spdif-tx {
				rockchip,pins = <0x02 0x17 0x01 0x66>;
				phandle = <0x61>;
			};
		};

		spi0 {

			spi0-clk {
				rockchip,pins = <0x01 0x1d 0x02 0x67>;
				phandle = <0x1e>;
			};

			spi0-cs0 {
				rockchip,pins = <0x01 0x18 0x03 0x67>;
				phandle = <0x21>;
			};

			spi0-cs1 {
				rockchip,pins = <0x01 0x19 0x03 0x67>;
			};

			spi0-tx {
				rockchip,pins = <0x01 0x17 0x03 0x67>;
				phandle = <0x1f>;
			};

			spi0-rx {
				rockchip,pins = <0x01 0x16 0x03 0x67>;
				phandle = <0x20>;
			};
		};

		spi1 {

			spi1-clk {
				rockchip,pins = <0x01 0x0e 0x02 0x67>;
				phandle = <0x22>;
			};

			spi1-cs0 {
				rockchip,pins = <0x01 0x0f 0x02 0x67>;
				phandle = <0x25>;
			};

			spi1-cs1 {
				rockchip,pins = <0x03 0x1c 0x02 0x67>;
			};

			spi1-rx {
				rockchip,pins = <0x01 0x10 0x02 0x67>;
				phandle = <0x24>;
			};

			spi1-tx {
				rockchip,pins = <0x01 0x11 0x02 0x67>;
				phandle = <0x23>;
			};
		};

		spi2 {

			spi2-clk {
				rockchip,pins = <0x00 0x0c 0x02 0x67>;
				phandle = <0x26>;
			};

			spi2-cs0 {
				rockchip,pins = <0x00 0x0d 0x02 0x67>;
				phandle = <0x29>;
			};

			spi2-rx {
				rockchip,pins = <0x00 0x0a 0x02 0x67>;
				phandle = <0x28>;
			};

			spi2-tx {
				rockchip,pins = <0x00 0x0b 0x02 0x67>;
				phandle = <0x27>;
			};
		};

		tsadc {

			otp-pin {
				rockchip,pins = <0x00 0x03 0x00 0x66>;
				phandle = <0x3b>;
			};

			otp-out {
				rockchip,pins = <0x00 0x03 0x01 0x66>;
				phandle = <0x3c>;
			};
		};

		uart0 {

			uart0-xfer {
				rockchip,pins = <0x02 0x18 0x01 0x67 0x02 0x19 0x01 0x66>;
				phandle = <0x2e>;
			};

			uart0-cts {
				rockchip,pins = <0x02 0x1a 0x01 0x66>;
				phandle = <0x2f>;
			};

			uart0-rts {
				rockchip,pins = <0x02 0x1b 0x01 0x66>;
				phandle = <0x30>;
			};
		};

		uart1 {

			uart1-xfer {
				rockchip,pins = <0x00 0x14 0x03 0x67 0x00 0x15 0x03 0x66>;
				phandle = <0x35>;
			};

			uart1-cts {
				rockchip,pins = <0x00 0x16 0x03 0x66>;
			};

			uart1-rts {
				rockchip,pins = <0x00 0x17 0x03 0x66>;
			};
		};

		uart2 {

			uart2-xfer {
				rockchip,pins = <0x02 0x06 0x02 0x67 0x02 0x05 0x02 0x66>;
				phandle = <0x50>;
			};
		};

		uart3 {

			uart3-xfer {
				rockchip,pins = <0x03 0x1d 0x02 0x67 0x03 0x1e 0x03 0x66>;
			};

			uart3-cts {
				rockchip,pins = <0x03 0x10 0x02 0x66>;
			};

			uart3-rts {
				rockchip,pins = <0x03 0x11 0x02 0x66>;
			};
		};

		uart4 {

			uart4-xfer {
				rockchip,pins = <0x00 0x1b 0x03 0x67 0x00 0x1a 0x03 0x66>;
				phandle = <0x36>;
			};

			uart4-cts {
				rockchip,pins = <0x00 0x18 0x03 0x66>;
			};

			uart4-rts {
				rockchip,pins = <0x00 0x19 0x03 0x66>;
			};
		};

		bluetooth {

			bt-host-wake {
				rockchip,pins = <0x03 0x07 0x00 0x66>;
				phandle = <0x32>;
			};

			bt-reg-on {
				rockchip,pins = <0x03 0x02 0x00 0x67>;
				phandle = <0x34>;
			};

			bt-wake {
				rockchip,pins = <0x03 0x03 0x00 0x66>;
				phandle = <0x33>;
			};
		};

		leds {

			power-led {
				rockchip,pins = <0x00 0x04 0x00 0x66>;
				phandle = <0x6c>;
			};
		};

		phy {

			phy-rst {
				rockchip,pins = <0x03 0x0c 0x00 0x66>;
				phandle = <0x42>;
			};
		};

		pmic {

			pmic-int {
				rockchip,pins = <0x00 0x05 0x00 0x67>;
				phandle = <0x49>;
			};

			pmic-sleep {
				rockchip,pins = <0x00 0x00 0x02 0x66>;
				phandle = <0x4a>;
			};
		};

		sdio-pwrseq {

			wifi-reg-on {
				rockchip,pins = <0x03 0x05 0x00 0x66>;
				phandle = <0x6d>;
			};
		};

		sound {

			hp-det {
				rockchip,pins = <0x00 0x17 0x00 0x66>;
				phandle = <0x6b>;
			};
		};

		usb {

			host-vbus-drv {
				rockchip,pins = <0x03 0x11 0x00 0x66>;
				phandle = <0x6e>;
			};

			otg-vbus-drv {
				rockchip,pins = <0x00 0x11 0x00 0x66>;
				phandle = <0x6f>;
			};
		};

		wifi {

			wifi-host-wake {
				rockchip,pins = <0x03 0x06 0x00 0x66>;
				phandle = <0x19>;
			};
		};
	};

	chosen {
		stdout-path = "serial1:115200n8";
	};

	memory@0 {
		device_type = "memory";
		reg = <0x00 0x00 0x00 0x40000000>;
	};

	adc-key {
		compatible = "adc-keys";
		io-channels = <0x69 0x01>;
		io-channel-names = "buttons";
		poll-interval = <0x64>;
		keyup-threshold-microvolt = <0x1b7740>;

		button-recovery {
			label = "Recovery";
			linux,code = <0x168>;
			press-threshold-microvolt = <0x00>;
		};
	};

	analog-sound {
		compatible = "audio-graph-card";
		dais = <0x6a>;
		hp-det-gpio = <0x47 0x17 0x00>;
		label = "alc5640";
		routing = "Mic Jack\0MICBIAS1\0IN1P\0Mic Jack\0Headphone Jack\0HPOL\0Headphone Jack\0HPOR\0Speakers\0SPORP\0Speakers\0SPORN\0Speakers\0SPOLP\0Speakers\0SPOLN";
		widgets = "Microphone\0Mic Jack\0Headphone\0Headphone Jack\0Speaker\0Speakers";
		pinctrl-names = "default";
		pinctrl-0 = <0x6b>;
	};

	dc-12v-regulator {
		compatible = "regulator-fixed";
		regulator-name = "dc_12v";
		regulator-min-microvolt = <0xb71b00>;
		regulator-max-microvolt = <0xb71b00>;
		regulator-always-on;
		regulator-boot-on;
		phandle = <0x70>;
	};

	gmac-clk {
		compatible = "fixed-clock";
		clock-frequency = <0x2faf080>;
		clock-output-names = "ext_gmac";
		#clock-cells = <0x00>;
		phandle = <0x40>;
	};

	hub-avdd-regulator {
		compatible = "regulator-fixed";
		regulator-name = "hub_avdd";
		regulator-min-microvolt = <0x325aa0>;
		regulator-max-microvolt = <0x325aa0>;
		vin-supply = <0x13>;
		regulator-always-on;
		phandle = <0x43>;
	};

	leds {
		compatible = "gpio-leds";

		power-led {
			gpios = <0x47 0x04 0x00>;
			function = "power";
			color = <0x02>;
			default-state = "on";
			pinctrl-names = "default";
			pinctrl-0 = <0x6c>;
		};
	};

	sdio-pwrseq {
		compatible = "mmc-pwrseq-simple";
		clocks = <0x31 0x01>;
		clock-names = "ext_clock";
		reset-gpios = <0x18 0x05 0x01>;
		pinctrl-names = "default";
		pinctrl-0 = <0x6d>;
		phandle = <0x12>;
	};

	vcc-host-regulator {
		compatible = "regulator-fixed";
		gpio = <0x18 0x11 0x00>;
		regulator-name = "vcc_host";
		regulator-min-microvolt = <0x4c4b40>;
		regulator-max-microvolt = <0x4c4b40>;
		vin-supply = <0x48>;
		pinctrl-names = "default";
		pinctrl-0 = <0x6e>;
		enable-active-high;
		regulator-always-on;
	};

	vcc-lan-regulator {
		compatible = "regulator-fixed";
		regulator-name = "vcc_lan";
		regulator-min-microvolt = <0x325aa0>;
		regulator-max-microvolt = <0x325aa0>;
		vin-supply = <0x13>;
		regulator-always-on;
		phandle = <0x3f>;
	};

	vcc-otg-regulator {
		compatible = "regulator-fixed";
		gpio = <0x47 0x11 0x00>;
		regulator-name = "vcc_otg";
		regulator-min-microvolt = <0x4c4b40>;
		regulator-max-microvolt = <0x4c4b40>;
		vin-supply = <0x48>;
		pinctrl-names = "default";
		pinctrl-0 = <0x6f>;
		enable-active-high;
		regulator-always-on;
		phandle = <0x44>;
	};

	vcc-sys-regulator {
		compatible = "regulator-fixed";
		regulator-name = "vcc_sys";
		regulator-min-microvolt = <0x4c4b40>;
		regulator-max-microvolt = <0x4c4b40>;
		vin-supply = <0x70>;
		regulator-always-on;
		regulator-boot-on;
		phandle = <0x48>;
	};

	vdd10-usb-regulator {
		compatible = "regulator-fixed";
		regulator-name = "vdd10_usb";
		regulator-min-microvolt = <0xf4240>;
		regulator-max-microvolt = <0xf4240>;
		vin-supply = <0x71>;
		regulator-always-on;
		phandle = <0x45>;
	};
};
